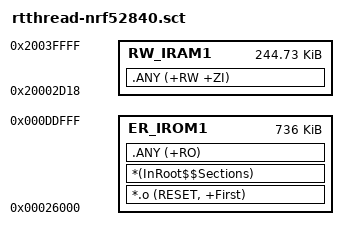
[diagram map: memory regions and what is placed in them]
; *************************************************************
; *** Scatter-Loading Description File generated by uVision ***
; *************************************************************

LR_IROM1 0x00026000 0x000B8000  {    ; load region size_region
  ER_IROM1 0x00026000 0x000B8000  {  ; load address = execution address
   *.o (RESET, +First)
   *(InRoot$$Sections)
   .ANY (+RO)
  }
  RW_IRAM1 0x20002D18 0x0003D2E8  {  ; RW data
   .ANY (+RW +ZI)
  }
}

